# K32W041AM register map
Vendor: nxp.com; File version: 1.0
CPU: CM4 r0p1, little endian, MPU, no FPU, VTOR, 3 interrupt priority bits
Registers are 32-bit, read-write, reset 0x0 unless marked. A register's access mark holds for its fields unless they carry their own. Offsets are from the block's base; [hi:lo] are bit positions; {n}, {i} and the like mark numbered series.

## GPIO — This is the description of component gpio It is General Purpose I/O with APB bus interface. More details will follow.
Base 0x40080000
{0x0+i} B[{i}] (i=0..21) 8-bit — Byte pin registers. Read 0: pin PIOn is LOW. Read 0xFF: pin PIOn is HIGH. Only 0 or 0xFF can be read. Write 0: clear output bit. Write any value 0x01 to 0xFF: set output bit. Reset values reflects the state of pin given by the relevant bit of PIN reset value
  [7:0] B
{0x1000+4i} W[{i}] (i=0..21) — Word pin registers Read 0: pin PIOn is LOW. Read 0xFFFFFFFF: pin PIOn is HIGH. Only 0 or 0xFFFF FFFF can be read. Write 0: clear output bit. Write any value 0x00000001 to 0xFFFFFFFF: set output bit. Reset values reflects the state of pin given by the relevant bit of PIN reset value
  [31:0] W
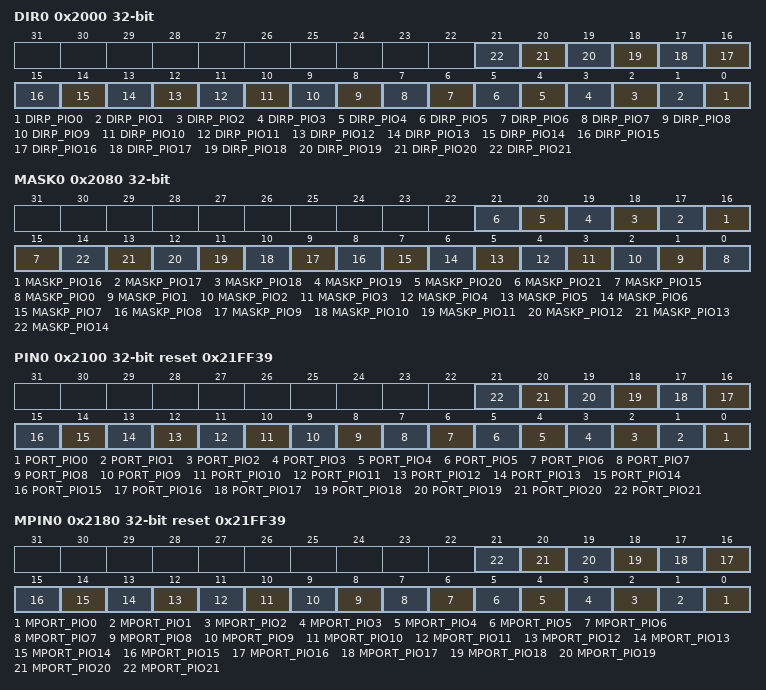
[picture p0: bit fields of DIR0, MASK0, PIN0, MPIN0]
0x2000 DIR0 — Direction register
  [n] DIRP_PIO{n} (n=0..21) — Selects pin direction for pin PIO{n} . 0 = input. 1 = output.
0x2080 MASK0 — Mask register
  [n] MASKP_PIO{n} (n=16..21) — Controls if PIO{n} is active in MPIN register. 0 = Mask bit is clear, the PIO will be active. 1 = Mask bit is set, the PIO will not be active.
  [15] MASKP_PIO15 — Controls if PIO150 is active in MPIN register. 0 = Mask bit is clear, the PIO will be active. 1 = Mask bit is set, the PIO will not be active.
  [n] MASKP_PIO{n} (n=0..14) — Controls if PIO{n} is active in MPIN register. 0 = Mask bit is clear, the PIO will be active. 1 = Mask bit is set, the PIO will not be active.
0x2100 PIN0 reset 0x21FF39 — Pin register
  [n] PORT_PIO{n} (n=0..21) — Reads pin states or loads output bits. 0 = Read: pin is low; write: clear output bit. 1 = Read: pin is high; write: set output bit.
0x2180 MPIN0 reset 0x21FF39 — Masked Pin register
  [n] MPORT_PIO{n} (n=0..21) — Masked pin register. 0 = Read: pin is LOW and/or the corresponding bit in the MASK register is 1; write: clear output bit if the corresponding bit in the MASK register is 0. 1 = Read: pin is HIGH and the corresponding bit in the MASK register is 0; write: set output bit if the corresponding bit in the MASK register is 0.
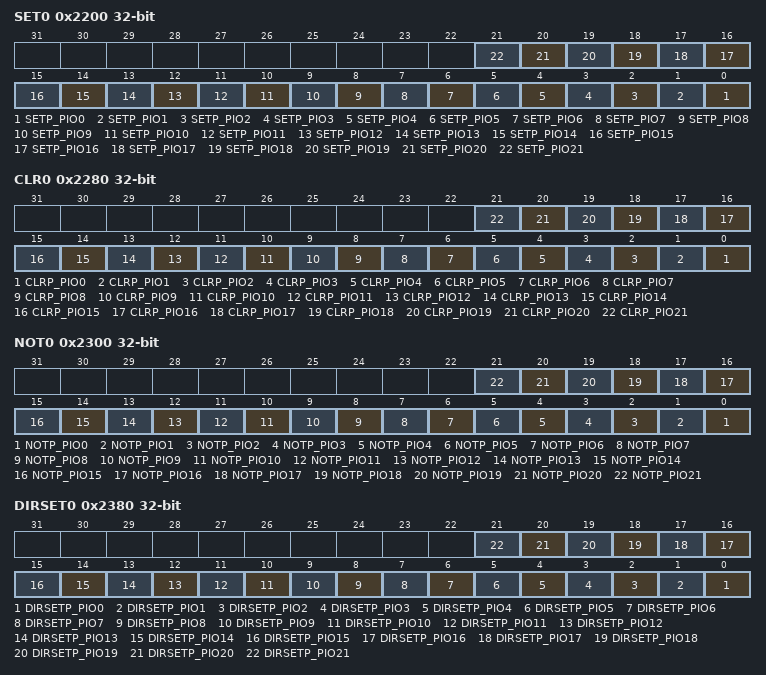
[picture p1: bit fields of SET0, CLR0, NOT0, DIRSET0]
0x2200 SET0 — Write: Set Pin register bits Read: output bits
  [n] SETP_PIO{n} (n=0..21) — Read or set output bits. 0 = Read: output bit: write: no operation. 1 = Read: output bit; write: set output bit.
0x2280 CLR0 wo reset not defined — Clear Pin register bits
  [n] CLRP_PIO{n} (n=0..21) — Clear output bits. 0 = No operation. 1 = Clear output bit.
0x2300 NOT0 wo reset not defined — Toggle Pin register bits
  [n] NOTP_PIO{n} (n=0..21) — Toggle output bits. 0 = no operation. 1 = Toggle output bit.
0x2380 DIRSET0 wo reset not defined — Set pin direction bits
  [n] DIRSETP_PIO{n} (n=0..21) — Set direction bits. 0 = no operation. 1 = Set direction bit.
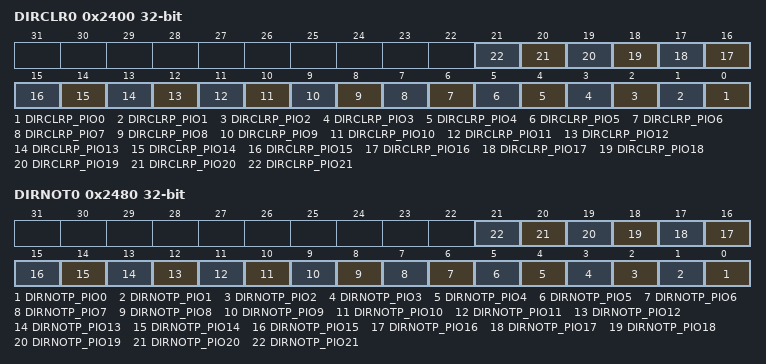
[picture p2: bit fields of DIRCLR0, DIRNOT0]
0x2400 DIRCLR0 wo reset not defined — Clear pin direction bits
  [n] DIRCLRP_PIO{n} (n=0..21) — Clear direction bits. 0 = no operation. 1 = Clear direction bit.
0x2480 DIRNOT0 wo reset not defined — Toggle pin direction bits
  [n] DIRNOTP_PIO{n} (n=0..21) — Toggle direction bits. 0 = no operation. 1 = Toggle direction bit.

## AES0 — This is the description of component aes256 It is AES 128-192-256 with GCM mode. More details will follow.
Base 0x40086000
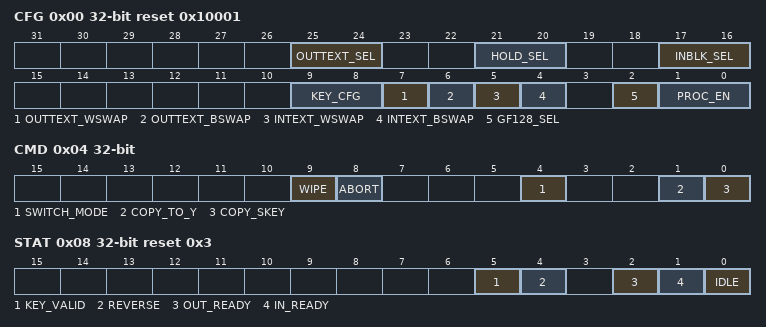
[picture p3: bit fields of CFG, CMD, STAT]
0x00 CFG reset 0x10001 — Configuration
  [25:24] OUTTEXT_SEL — Output Text Selection From: 00: Output Block. 01: Output Block XOR Input Text. 10: Output Block XOR Holding. 11: Reserved.
  [21:20] HOLD_SEL — Holding Select From: 00: Counter. 01: Input Text. 10: Output Block. 11: Input Text XOR Output Block.
  [17:16] INBLK_SEL — Input Block Selection From: 00: Reserved. 01: Input Text. 10: Holding. 11: Input Text XOR Holding.
  [9:8] KEY_CFG — Key Configuration. 00: 128 Bit Key. 01: 192 Bit Key. 10: 256 Bit Key. 11: Reserved.
  [7] OUTTEXT_WSWAP — Output Text Word Swap
  [6] OUTTEXT_BSWAP — Output Text Byte Swap
  [5] INTEXT_WSWAP — Input Text Word Swap
  [4] INTEXT_BSWAP — Input Text Byte Swap
  [2] GF128_SEL — GF128 Select Mode. 0: GF128 Hash Input Text. 1: GF128 Hash Output Text.
  [1:0] PROC_EN — Processing Mode Enable. 00: Reserved. 01: Encrypt/Decrypt Only. 10: GF128 Hash Only. 11: Encrypt/Decrypt and Hash.
0x04 CMD — Command
  [9] WIPE — Performs Abort, clears KEY, disables cipher, and clears GF128_Y
  [8] ABORT — Aborts Encrypt/Decrypt and GF128 Hash, clears INTEXT, clears OUTTEXT, and clears HOLDING
  [4] SWITCH_MODE — Switches mode from Forward to Reverse or from Reverse to Forward. Must wait for Idle after command. Typically used for non-counter modes (ECB, CBC, CFB, OFB) to switch from forward to reverse mode for decryption.
  [1] COPY_TO_Y — Copies Output Text to GF128 Y. Typically used for GCM where the Hash requires a Y input which is the result of an ECB encryption of 0s. Should be performed after encryption of 0s.
  [0] COPY_SKEY — Copies Secret Key and enables cipher. Secret key is typically held in OTP or other secure memory.
0x08 STAT reset 0x3 — Status
  [5] KEY_VALID — When set, Key is valid
  [4] REVERSE — When set, Cipher in reverse mode
  [2] OUT_READY — When set, output Text can be read
  [1] IN_READY — When set, input Text can be written
  [0] IDLE — When set, all state machines are idle
0x0C CTR_INCR — Counter Increment. Increment value for HOLDING when in Counter modes
{0x20+4i} KEY[{i}] (i=0..7) wo — Bits of the AES key
  [31:0] KEY — Contains the bits of the AES key.
{0x40+4i} INTEXT[{i}] (i=0..3) wo — Input text bits
  [31:0] INTEXT — Contains bits of the AES key.
{0x50+4i} HOLDING[{i}] (i=0..3) wo — Holding register bits
  [31:0] HOLDING — Contains the first word (bits 31:0) of the 128 bit Holding value.
{0x60+4i} OUTTEXT[{i}] (i=0..3) ro — Output text bits
  [31:0] OUTTEXT — Contains the bits of the 128 bit Output text data.
{0x70+4i} GF128_Y[{i}] (i=0..3) wo — Y bits input of GF128 hash
  [31:0] GF128_Y — Contains the bits of the Y input of GF128 hash.
{0x80+4i} GF128_Z[{i}] (i=0..3) ro — Result bits of GF128 hash
  [31:0] GF128_Z — Contains bits of the result of GF128 hash.
{0x90+4i} GCM_TAG[{i}] (i=0..3) ro — GCM Tag bits
  [31:0] GCM_TAG — Contains bits of the 128 bit GCM tag.

## FLEXCOMM0 — LPC5411x Flexcomm serial communication
Base 0x4008B000
Same registers: FLEXCOMM2 0x40003000, FLEXCOMM3 0x40004000, FLEXCOMM6 0x40005000, FLEXCOMM1 0x4008C000, FLEXCOMM4 0x4008D000, FLEXCOMM5 0x4008E000
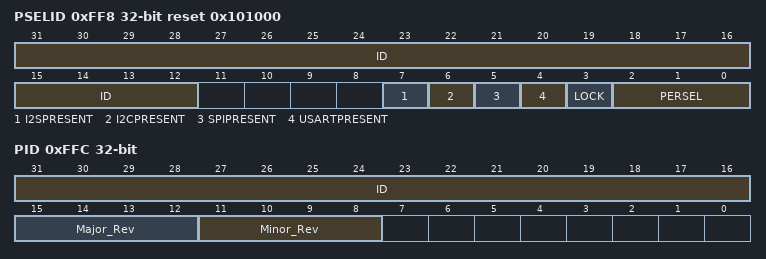
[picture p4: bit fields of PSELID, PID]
0xFF8 PSELID reset 0x101000 — Peripheral Select and Flexcomm ID register.
  [31:12] ID ro — Flexcomm ID.
  [7] I2SPRESENT ro — I 2S present indicator. This field is Read-only.
    0=NOT_PRESENT (This Flexcomm does not include the I2S function.); 1=PRESENT (This Flexcomm includes the I2S function.)
  [6] I2CPRESENT ro — I2C present indicator. This field is Read-only.
    0=NOT_PRESENT (This Flexcomm does not include the I2C function.); 1=PRESENT (This Flexcomm includes the I2C function.)
  [5] SPIPRESENT ro — SPI present indicator. This field is Read-only.
    0=NOT_PRESENT (This Flexcomm does not include the SPI function.); 1=PRESENT (This Flexcomm includes the SPI function.)
  [4] USARTPRESENT ro — USART present indicator. This field is Read-only.
    0=NOT_PRESENT (This Flexcomm does not include the USART function.); 1=PRESENT (This Flexcomm includes the USART function.)
  [3] LOCK — Lock the peripheral select. This field is writable by software.
    0=UNLOCKED (Peripheral select can be changed by software.); 1=LOCKED (Peripheral select is locked and cannot be changed until this Flexcomm or the entire device is reset.)
  [2:0] PERSEL — Peripheral Select. This field is writable by software.
    0=NO_PERIPH_SELECTED (No peripheral selected.); 1=USART (USART function selected.); 2=SPI (SPI function selected.); 3=I2C (I2C function selected.); 4=I2S_TRANSMIT (I2S transmit function selected.); 5=I2S_RECEIVE (I2S receive function selected.)
0xFFC PID — Peripheral identification register.
  [31:16] ID — Module identifier for the selected function.
  [15:12] Major_Rev ro — Major revision of module implementation.
  [11:8] Minor_Rev ro — Minor revision of module implementation.
